# TCM register map
Vendor: Texas Instruments
Peripheral module from a debugger description file (folder CC27xxx10).
Registers are 32-bit, access per field, reset 0x0 unless marked. A register's access mark holds for its fields unless they carry their own. Offsets are as the file gives them; lines under a group give offsets from that group; [hi:lo] are bit positions; {n}, {i} and the like mark numbered series; 'fields as' and 'values as' point back to an identical list; <NAME> marks a mode.

## TCM — IO Controller
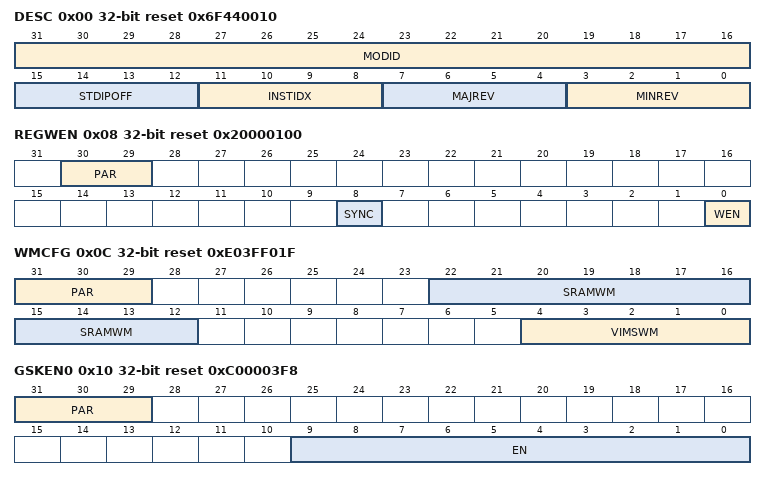
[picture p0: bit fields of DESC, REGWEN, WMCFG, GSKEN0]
0x00 DESC rw reset 0x6F440010 — This register identifies the peripheral and its exact version. This register is strictly read-only. Any write to this register will trigger chip reset.
  [31:16] MODID — Module identification contains a unique peripheral identification number.
    0xFFFF=MAXIMUM (Highest possible value); 0=MINIMUM (Smallest value)
  [15:12] STDIPOFF — Standard IP registers offset. Value 0 indicates Standard IP registers are not present. Any other value between 1 to 15 indicates standard IP registers start from address offset 64 * STDIPOFF from base address.
    15=MAXIMUM (Highest possible value); 0=MINIMUM (Smallest value)
  [11:8] INSTIDX — Instance Index within the device. This will be a parameter to the RTL for modules that can have multiple instances.
    values as STDIPOFF
  [7:4] MAJREV — Major rev of the IP
    values as STDIPOFF
  [3:0] MINREV — Minor rev of the IP
    values as STDIPOFF
0x04 DESCEX reset 0x29 — This register identifies the peripheral and its exact version. This register is strictly read-only. Any write to this register will trigger chip reset.
  [8:0] GSKCNT rw — Number of gaskets
0x08 REGWEN reset 0x20000100 — This register blocks writes to all the MMR of TCM once set. This register is protected by odd parity bit. It is sticky 1.
  [30:29] PAR rw — Parity bit
    {v}=Value {v} (v=0..3)
  [8] SYNC rw — Program this bit to 0 before writing to WMCFG or any of the gasket enable MMR i.e. GSKEN0, GSKEN1 etc. Once the MMR writes are done, program this bit to 1 again. Then WEN can be programmed 1 to lock the configuration. Note: Do not toggle SYNC and WEN in the same cycle
    1=RESET; 0=SET
  [0] WEN rw — Write enable
    1=DISABLE (Highest possible value); 0=ENABLE (Smallest value)
0x0C WMCFG reset 0xE03FF01F — This register is used to configure SRAM and VIMS watermark. This register is protected by odd parity bits.
  [31:29] PAR rw — Parity bits. Bit 28 stores the odd parity for bits 0 to 7. Bit 29 stores the odd parity of bits 8 to 15. Bit 30 stores the odd parity of bits 23 to 16.
    {v}=Value {v} (v=0..7)
  [22:12] SRAMWM rw — SRAM Watermark
    0x1FF=MAXIMUM (Highest possible value); 0=MINIMUM (Smallest value)
  [4:0] VIMSWM rw — VIMS Watermark
0x10 GSKEN0 reset 0xC00003F8 — This register is used to store gasket configuration. This register is protected by odd parity bits.
  [31:29] PAR rw — Parity bits. Bit 29 stores the odd parity for bits 0 to 7. Bit 30 stores the odd parity of bits 8 to 15. Bit 31 stores the odd parity of bits 23 to 16.
    {v}=Value {v} (v=0..7)
  [9:0] EN rw — Gasket enable. The gasket bit to IP mapping is given as follows :- [0] = DMA initiator AHB gasket enable [1] = I2S initiator AHB gasket enable [2] = HSM initiator AHB gasket enable [3] = Radio target AHB gasket enable [4] = AES target AHB gasket enable [5] = I2S target AHB gasket enable [6] = PDM target AHB gasket enable [7] = AFA target AHB gasket enable [8] = DMA target AHB gasket enable [9] = CANFD target AHB gasket enable [10] = VCE target AHB gasket enable [11] = VCERAM target AHB gasket enable [12] = GPIO target APB gasket enable [13] = SYSTIMER target APB gasket enable [14] = UART0 target APB gasket enable [15] = UART1 target APB gasket enable [16] = SPI0 target APB gasket enable [17] = SPI1 target APB gasket enable [18] = I2C0 target APB gasket enable [19] = EVTSVT target APB gasket enable [20] = ADC target APB gasket enable [21] = MICADC target APB gasket enable [22] = MICPGA target APB gasket enable [23] = CLKCTRL target APB gasket enable
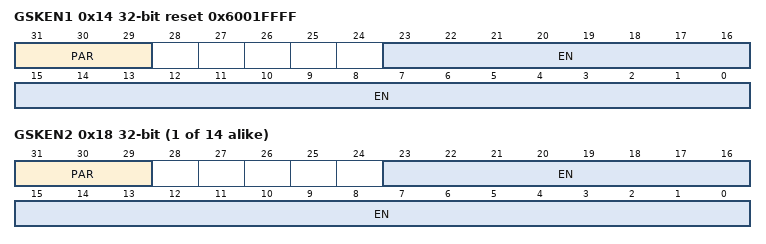
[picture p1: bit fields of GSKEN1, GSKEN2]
0x14 GSKEN1 reset 0x6001FFFF — This register is used to store gasket configuration. This register is protected by odd parity bits.
  [31:29] PAR rw — Parity bits. Bit 29 stores the odd parity for bits 0 to 7. Bit 30 stores the odd parity of bits 8 to 15. Bit 31 stores the odd parity of bits 23 to 16.
    {v}=Value {v} (v=0..7)
  [23:0] EN rw — Gasket enable. The gasket bit to IP mapping is given as follows :- [0] = LGPT target APB gasket enable [1] = NOWRAPPER target APB gasket enable [2] = VIMS target APB gasket enable [3] = HSM target APB gasket enable [4] = PMC target APB gasket enable [5] = CKMDIG target APB gasket enable [6] = RTC target APB gasket enable [7] = IOC target APB gasket enable [8] = SYS0 target APB gasket enable [9] = EVTULL target APB gasket enable [10] = PMUDIG target APB gasket enable [11] = DEBUGSS target APB gasket enable [12] = HSM mailbox target APB gasket enable [13] = HSM mailbox target APB gasket enable [14] = HSM mailbox target APB gasket enable [15] = HSM mailbox target APB gasket enable [16] = HSM config target APB gasket enable
    0xFFFFFF=MAXIMUM (Highest possible value); 0=MINIMUM (Smallest value)
{0x10+4i} GSKEN{i} (i=2..15) — This register is used to store gasket configuration. This register is protected by odd parity bits.
  [31:29] PAR rw — Parity bits. Bit 29 stores the odd parity for bits 0 to 7. Bit 30 stores the odd parity of bits 8 to 15. Bit 31 stores the odd parity of bits 23 to 16.
    {v}=Value {v} (v=0..7)
  [23:0] EN rw — Gasket enable
    values as GSKEN1.EN
